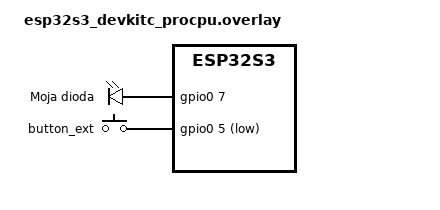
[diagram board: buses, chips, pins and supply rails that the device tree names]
/{
	aliases{
		my-led=&yellow_led;
		my-button=&button_ext;
	};
	leds{
		compatible = "gpio-leds";
		yellow_led: led1 {
			gpios=<&gpio0 7 GPIO_ACTIVE_HIGH>;
			label="Moja dioda";
		};
	};
	buttons{
		compatible = "gpio-keys";
		debounce-interval-ms = <50>;
		button_ext:button1 {
			 gpios = <&gpio0 5 (GPIO_PULL_UP | GPIO_ACTIVE_LOW)>;
		};
	};
};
